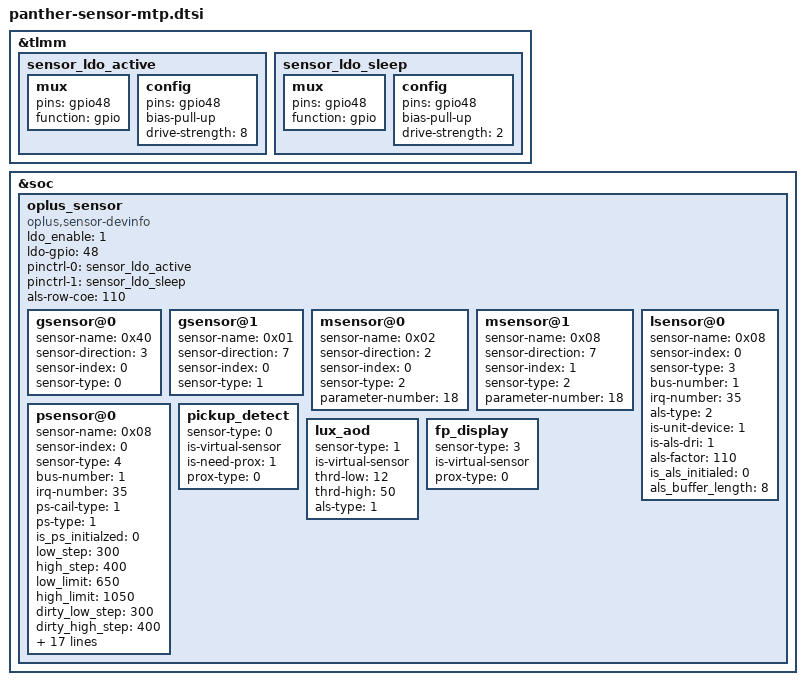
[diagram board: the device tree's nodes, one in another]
&tlmm {
		sensor_ldo_active: sensor_ldo_active {
			mux {
				pins = "gpio48";
				function = "gpio";
			};
			config {
				pins = "gpio48";
				bias-pull-up;
				drive-strength = <8>;
			};
		   };
		sensor_ldo_sleep: sensor_ldo_sleep {
			mux {
				pins = "gpio48";
				function = "gpio";
			};
			config {
				pins = "gpio48";
				bias-pull-up;
				drive-strength = <2>;
			};
		};
};
&soc {
	oplus_sensor {
			ldo_enable = <1>;
			ldo-gpio = <48>;
			compatible = "oplus,sensor-devinfo";

			pinctrl-names = "sensor_ldo_active" , "sensor_ldo_sleep";
			pinctrl-0 = <&sensor_ldo_active>;
			pinctrl-1 = <&sensor_ldo_sleep>;

			als-row-coe = <110>;
			/*enum {LSM6DSM = 0x01, BMI160 = 0x02, LSM6DS3 = 0x04, BMI260 = 0x08};*/
			gsensor@0 {
					sensor-name = <0x40>;//ICM4X607
					sensor-direction = <3>;
					sensor-index = <0>;//source num
					sensor-type = <0>;//OPPO_ACCEL
			};
			gsensor@1 {
					sensor-name = <0x01>;//BMI22X
					sensor-direction = <7>;
					sensor-index = <0>;//source num
					sensor-type = <1>;//OPLUS_GYROSCOPE
			};
			msensor@0 {
					sensor-name = <0x02>;//MMC5603
					sensor-direction = <2>;
					sensor-index = <0>;
					sensor-type = <2>;//OPPO_MAG
					parameter-number= <18>;
			};
			msensor@1 {
					sensor-name = <0x08>;//QMC6308
					sensor-direction = <7>;
					sensor-index = <1>;
					sensor-type = <2>;//OPLUS_MAG
					parameter-number= <18>;
			};
			/*enum {STK3A5X=0x01,TCS3701=0x02,TCS3408=0x04,STK326X=0x08,MN78911=0x10};*/
			/*enum {NORMAL=0x01,UNDER_LCD=0x02,VIRTUAL_UNDER_LCD=0x03}*/
			lsensor@0 {
					sensor-name = <0x08>;//stk326x
					sensor-index = <0>;
					sensor-type = <3>;//OPLUS_ALS
					bus-number = <1>;
					irq-number = <35>;
					als-type = <2>;//UNDER_LCD
					is-unit-device = <1>;
					is-als-dri = <1>;
					als-factor = <110>;
					is_als_initialed = <0>;
					als_buffer_length = <8>;
			};
			psensor@0 {
					sensor-name = <0x08>;//stk326x
					sensor-index = <0>;
					sensor-type = <4>;//OPLUS_PROXIMITY
					bus-number = <1>;
					irq-number = <35>;
					ps-cail-type = <1>;
					ps-type = <1>;
					is_ps_initialzed = <0>;
					low_step = <300>;
					high_step = <400>;
					low_limit = <650>;
					high_limit = <1050>;
					dirty_low_step = <300>;
					dirty_high_step = <400>;
					ps_dirty_limit = <1800>;
					ps_ir_limit = <2000>;
					ps_adjust_min = <0>;
					ps_adjust_max = <1850>;
					sampling_count = <5>;
					step_max = <400>;
					step_min = <100>;
					step_div = <2000>;
					anti_shake_delta = <70>;
					dynamic_cali_max = <5000>;
					raw2offset_radio = <1000>;
					offset_max = <60000>;
					offset_range_min = <0>;
					offset_range_max = <65536>;
					force_cali_limit = <2000>;
					cali_jitter_limit = <20>;
					cal_offset_margin = <3000>;
			};
			/*virtual sensor
			enum sensor_algo_id {
					OPPO_PICKUP_DETECT,
					OPPO_LUX_AOD,
					OPPO_TP_GESTURE,
					OPPO_FP_DISPLAY,
					OPPO_FREE_FALL,
					OPPO_CAMERA_PROTECT,
					SENSOR_ALGO_NUM
			}*/
			pickup_detect {
					sensor-type = <0>; //OPPO_PICKUP_DETECT
					is-virtual-sensor;
					is-need-prox = <1>;
					prox-type = <0>; // 0 - proximity; 1 - proximity_fake
			};
			lux_aod {
					sensor-type = <1>; //OPPO_LUX_AOD
					is-virtual-sensor;
					thrd-low = <12>;
					thrd-high = <50>;
					als-type = <1>; // 0 - ambient_light; 1 - wise_light
			};
			fp_display {
					sensor-type = <3>; //OPPO_FP_DISPLAY
					is-virtual-sensor;
					prox-type = <0>; // 0 - proximity; 1 - proximity_fake
			};
	};
};
